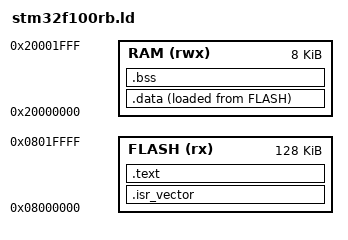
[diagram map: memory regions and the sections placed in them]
/* Minimal linker script for STM32F100RB */
MEMORY
{
  FLASH (rx) : ORIGIN = 0x08000000, LENGTH = 128K
  RAM (rwx)  : ORIGIN = 0x20000000, LENGTH = 8K
}

SECTIONS
{
  .isr_vector :
  {
    . = ALIGN(4);
    KEEP(*(.isr_vector))
    . = ALIGN(4);
  } > FLASH

  .text :
  {
    . = ALIGN(4);
    *(.text)
    *(.text*)
    *(.rodata)
    *(.rodata*)
    . = ALIGN(4);
  } > FLASH

  .data :
  {
    . = ALIGN(4);
    _sdata = .;
    *(.data)
    *(.data*)
    . = ALIGN(4);
    _edata = .;
  } > RAM AT > FLASH

  _sidata = LOADADDR(.data);

  .bss :
  {
    . = ALIGN(4);
    _sbss = .;
    *(.bss)
    *(.bss*)
    *(COMMON)
    . = ALIGN(4);
    _ebss = .;
  } > RAM

  /DISCARD/ :
  {
    libc.a ( * )
    libm.a ( * )
    libgcc.a ( * )
  }
}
